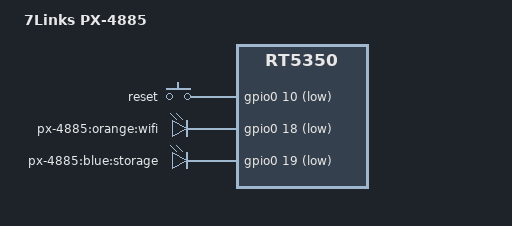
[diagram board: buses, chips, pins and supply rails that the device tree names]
/include/ "rt5350.dtsi"

/ {
	compatible = "PX-4885", "ralink,rt5350-soc";
	model = "7Links PX-4885";

	pinctrl {
		state_default: pinctrl0 {
			gpio {
				ralink,group = "i2c", "jtag", "uartf";
				ralink,function = "gpio";
			};
		};
	};

	ethernet@10100000 {
		mtd-mac-address = <&factory 0x28>;
	};

	esw@10110000 {
		mediatek,portmap = <0x3f>;
	};

	wmac@10180000 {
		ralink,mtd-eeprom = <&factory 0>;
	};

	gpio-keys-polled {
		compatible = "gpio-keys-polled";
		#address-cells = <1>;
		#size-cells = <0>;
		poll-interval = <20>;

		reset {
			label = "reset";
			gpios = <&gpio0 10 1>;
			linux,code = <0x198>;
		};
	};

	gpio-leds {
		compatible = "gpio-leds";

		orange {
			label = "px-4885:orange:wifi";
			gpios = <&gpio0 18 1>;
		};

		blue {
			label = "px-4885:blue:storage";
			gpios = <&gpio0 19 1>;
		};
	};
};
